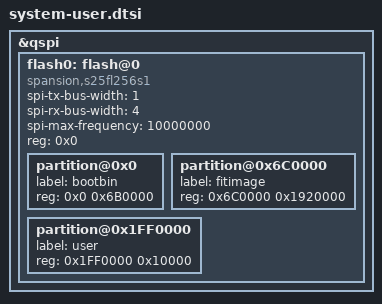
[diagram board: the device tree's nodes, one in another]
/include/ "system-conf.dtsi"

&qspi {
 #address-cells = <1>;
 #size-cells = <0>;

 flash0: flash@0 {
  compatible = "spansion,s25fl256s1";
  spi-tx-bus-width = <1>;
  spi-rx-bus-width = <4>;
  spi-max-frequency = <10000000>;
  reg = <0x0>;
  #address-cells = <1>;
  #size-cells = <1>;

  partition@0x0{
   label = "bootbin";
   // start: 0          end: 0x6B0000     size: 0x6B0000    (7012352 bytes ~7MB)
   reg = <0x0 0x6B0000>;
  };

  partition@0x6C0000{
   label = "fitimage";
   // start: 0x6C0000   end: 0x1FE0000    size: 0x1920000   (26345472 bytes ~26MB)
   reg = <0x6C0000 0x1920000>;
  };

  // start: 0x1FF0000   end: 0x2000000    size: 0x10000     (65536 bytes 64kB)
  partition@0x1FF0000{
   label = "user";
   reg = <0x1FF0000 0x10000>;
  };
 };
};

